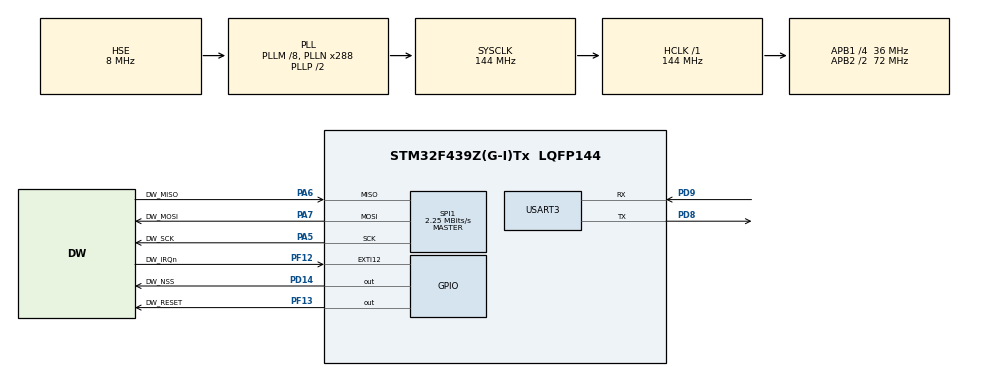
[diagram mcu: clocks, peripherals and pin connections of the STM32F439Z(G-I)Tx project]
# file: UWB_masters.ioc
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FREERTOS.Tasks01=defaultTask,24,128,StartDefaultTask,Default,NULL,Dynamic,NULL,NULL
Mcu.Family=STM32F4
Mcu.Name=STM32F439Z(G-I)Tx
Mcu.Package=LQFP144
NVIC.PriorityGroup=NVIC_PRIORITYGROUP_4
NVIC.TIM1_UP_TIM10_IRQn=true\:15\:0\:false\:false\:true\:false\:false\:true\:true
NVIC.TimeBase=TIM1_UP_TIM10_IRQn
NVIC.TimeBaseIP=TIM1
PA13.Mode=Serial_Wire
PA13.Signal=SYS_JTMS-SWDIO
PA14.Mode=Serial_Wire
PA14.Signal=SYS_JTCK-SWCLK
PA5.GPIO_Label=DW_SCK
PA5.Mode=Full_Duplex_Master
PA5.Signal=SPI1_SCK
PA6.GPIO_Label=DW_MISO
PA6.Mode=Full_Duplex_Master
PA6.Signal=SPI1_MISO
PA7.GPIO_Label=DW_MOSI
PA7.Mode=Full_Duplex_Master
PA7.Signal=SPI1_MOSI
PC14/OSC32_IN.Mode=LSE-External-Oscillator
PC14/OSC32_IN.Signal=RCC_OSC32_IN
PC15/OSC32_OUT.Mode=LSE-External-Oscillator
PC15/OSC32_OUT.Signal=RCC_OSC32_OUT
PD14.GPIO_Label=DW_NSS
PD14.GPIO_PuPd=GPIO_PULLUP
PD14.GPIO_Speed=GPIO_SPEED_FREQ_MEDIUM
PD14.PinState=GPIO_PIN_SET
PD14.Signal=GPIO_Output
PD8.Mode=Asynchronous
PD8.Signal=USART3_TX
PD9.Mode=Asynchronous
PD9.Signal=USART3_RX
PF12.GPIO_Label=DW_IRQn
PF12.Signal=GPXTI12
PF13.GPIO_Label=DW_RESET
PF13.GPIO_ModeDefaultOutputPP=GPIO_MODE_OUTPUT_OD
PF13.GPIO_PuPd=GPIO_NOPULL
PF13.GPIO_Speed=GPIO_SPEED_FREQ_MEDIUM
PF13.Signal=GPIO_Output
PH0/OSC_IN.GPIO_Label=MCO [STM32F103CBT6_PA8]
PH0/OSC_IN.Mode=HSE-External-Clock-Source
PH0/OSC_IN.Signal=RCC_OSC_IN
PH1/OSC_OUT.Mode=HSE-External-Clock-Source
PH1/OSC_OUT.Signal=RCC_OSC_OUT
ProjectManager.HeapSize=0x200
ProjectManager.StackSize=0x400
ProjectManager.TargetToolchain=STM32CubeIDE
RCC.48MHZClocksFreq_Value=72000000
RCC.AHBFreq_Value=144000000
RCC.APB1CLKDivider=RCC_HCLK_DIV4
RCC.APB1Freq_Value=36000000
RCC.APB1TimFreq_Value=72000000
RCC.APB2CLKDivider=RCC_HCLK_DIV2
RCC.APB2Freq_Value=72000000
RCC.APB2TimFreq_Value=144000000
RCC.CortexFreq_Value=144000000
RCC.HCLKFreq_Value=144000000
RCC.HSE_VALUE=8000000
RCC.HSI_VALUE=16000000
RCC.PLLM=8
RCC.PLLN=288
RCC.PLLSourceVirtual=RCC_PLLSOURCE_HSE
RCC.PWR_Regulator_Voltage_Scale=PWR_REGULATOR_VOLTAGE_SCALE1
RCC.SYSCLKFreq_VALUE=144000000
RCC.SYSCLKSource=RCC_SYSCLKSOURCE_PLLCLK
RCC.VCOOutputFreq_Value=288000000
SPI1.BaudRatePrescaler=SPI_BAUDRATEPRESCALER_32
SPI1.CalculateBaudRate=2.25 MBits/s
SPI1.Direction=SPI_DIRECTION_2LINES
SPI1.Mode=SPI_MODE_MASTER
SPI1.VirtualType=VM_MASTER
USART3.VirtualMode=VM_ASYNC
VP_FREERTOS_VS_CMSIS_V2.Mode=CMSIS_V2
VP_SYS_VS_tim1.Mode=TIM1
board=custom

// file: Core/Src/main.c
/* USER CODE BEGIN Header */
/**
  ******************************************************************************
  * @file           : main.c
  * @brief          : Main program body
  ******************************************************************************
  * @attention
  *
  * Copyright (c) 2025 STMicroelectronics.
  * All rights reserved.
  *
  * This software is licensed under terms that can be found in the LICENSE file
  * in the root directory of this software component.
  * If no LICENSE file comes with this software, it is provided AS-IS.
  *
  ******************************************************************************
  */
/* USER CODE END Header */
#include "main.h"
#include "cmsis_os.h"
#include "spi.h"
#include "usart.h"
#include "gpio.h"

void SystemClock_Config(void);
void MX_FREERTOS_Init(void);

int main(void)
{

  /* MCU Configuration--------------------------------------------------------*/

  /* Reset of all peripherals, Initializes the Flash interface and the Systick. */
  HAL_Init();

  /* Configure the system clock */
  SystemClock_Config();

  /* Initialize all configured peripherals */
  MX_GPIO_Init();
  MX_SPI1_Init();
  MX_USART3_UART_Init();

  /* Init scheduler */
  osKernelInitialize();

  /* Call init function for freertos objects (in cmsis_os2.c) */
  MX_FREERTOS_Init();

  /* Start scheduler */
  osKernelStart();

  /* We should never get here as control is now taken by the scheduler */

  /* Infinite loop */
  while (1)
  {

  }
}

void SystemClock_Config(void)
{
  RCC_OscInitTypeDef RCC_OscInitStruct = {0};
  RCC_ClkInitTypeDef RCC_ClkInitStruct = {0};

  /** Configure the main internal regulator output voltage
  */
  __HAL_RCC_PWR_CLK_ENABLE();
  __HAL_PWR_VOLTAGESCALING_CONFIG(PWR_REGULATOR_VOLTAGE_SCALE1);

  /** Initializes the RCC Oscillators according to the specified parameters
  * in the RCC_OscInitTypeDef structure.
  */
  RCC_OscInitStruct.OscillatorType = RCC_OSCILLATORTYPE_HSE;
  RCC_OscInitStruct.HSEState = RCC_HSE_BYPASS;
  RCC_OscInitStruct.PLL.PLLState = RCC_PLL_ON;
  RCC_OscInitStruct.PLL.PLLSource = RCC_PLLSOURCE_HSE;
  RCC_OscInitStruct.PLL.PLLM = 8;
  RCC_OscInitStruct.PLL.PLLN = 288;
  RCC_OscInitStruct.PLL.PLLP = RCC_PLLP_DIV2;
  RCC_OscInitStruct.PLL.PLLQ = 4;
  if (HAL_RCC_OscConfig(&RCC_OscInitStruct) != HAL_OK)
  {
    Error_Handler();
  }

  /** Initializes the CPU, AHB and APB buses clocks
  */
  RCC_ClkInitStruct.ClockType = RCC_CLOCKTYPE_HCLK|RCC_CLOCKTYPE_SYSCLK
                              |RCC_CLOCKTYPE_PCLK1|RCC_CLOCKTYPE_PCLK2;
  RCC_ClkInitStruct.SYSCLKSource = RCC_SYSCLKSOURCE_PLLCLK;
  RCC_ClkInitStruct.AHBCLKDivider = RCC_SYSCLK_DIV1;
  RCC_ClkInitStruct.APB1CLKDivider = RCC_HCLK_DIV4;
  RCC_ClkInitStruct.APB2CLKDivider = RCC_HCLK_DIV2;

  if (HAL_RCC_ClockConfig(&RCC_ClkInitStruct, FLASH_LATENCY_4) != HAL_OK)
  {
    Error_Handler();
  }
}

void HAL_TIM_PeriodElapsedCallback(TIM_HandleTypeDef *htim)
{
  if (htim->Instance == TIM1)
  {
    HAL_IncTick();
  }
}

void Error_Handler(void)
{
  __disable_irq();
  while (1)
  {
  }
}

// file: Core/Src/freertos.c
/* USER CODE BEGIN Header */
/**
  ******************************************************************************
  * File Name          : freertos.c
  * Description        : Code for freertos applications
  ******************************************************************************
  * @attention
  *
  * Copyright (c) 2025 STMicroelectronics.
  * All rights reserved.
  *
  * This software is licensed under terms that can be found in the LICENSE file
  * in the root directory of this software component.
  * If no LICENSE file comes with this software, it is provided AS-IS.
  *
  ******************************************************************************
  */
/* USER CODE END Header */

#include "FreeRTOS.h"
#include "task.h"
#include "main.h"
#include "cmsis_os.h"

/* USER CODE BEGIN Includes */
#include "example_app.h"
#include "main_app.h"
/* USER CODE END Includes */

/* USER CODE BEGIN PD */
 //#define EXAMPLE_APP
#define MAIN_APP
/* USER CODE END PD */

/* Definitions for defaultTask */
osThreadId_t defaultTaskHandle;
const osThreadAttr_t defaultTask_attributes = {
  .name = "defaultTask",
  .stack_size = 128 * 4,
  .priority = (osPriority_t) osPriorityNormal,
};

void StartDefaultTask(void *argument);

void MX_FREERTOS_Init(void); /* (MISRA C 2004 rule 8.1) */

void MX_FREERTOS_Init(void) {

  /* Create the thread(s) */
  /* creation of defaultTask */
  defaultTaskHandle = osThreadNew(StartDefaultTask, NULL, &defaultTask_attributes);

  /* USER CODE BEGIN RTOS_THREADS */
#if defined(EXAMPLE_APP)
  xTaskCreate(example_app_task, "ExampleAppTask", 512, NULL, 1, NULL);
#elif defined(MAIN_APP)
  xTaskCreate(main_app_task, "MainAppTask", 512, NULL, 1, NULL);
#endif
  /* USER CODE END RTOS_THREADS */

}

void StartDefaultTask(void *argument)
{
  /* USER CODE BEGIN StartDefaultTask */
  vTaskDelete(NULL);
  /* USER CODE END StartDefaultTask */
}
